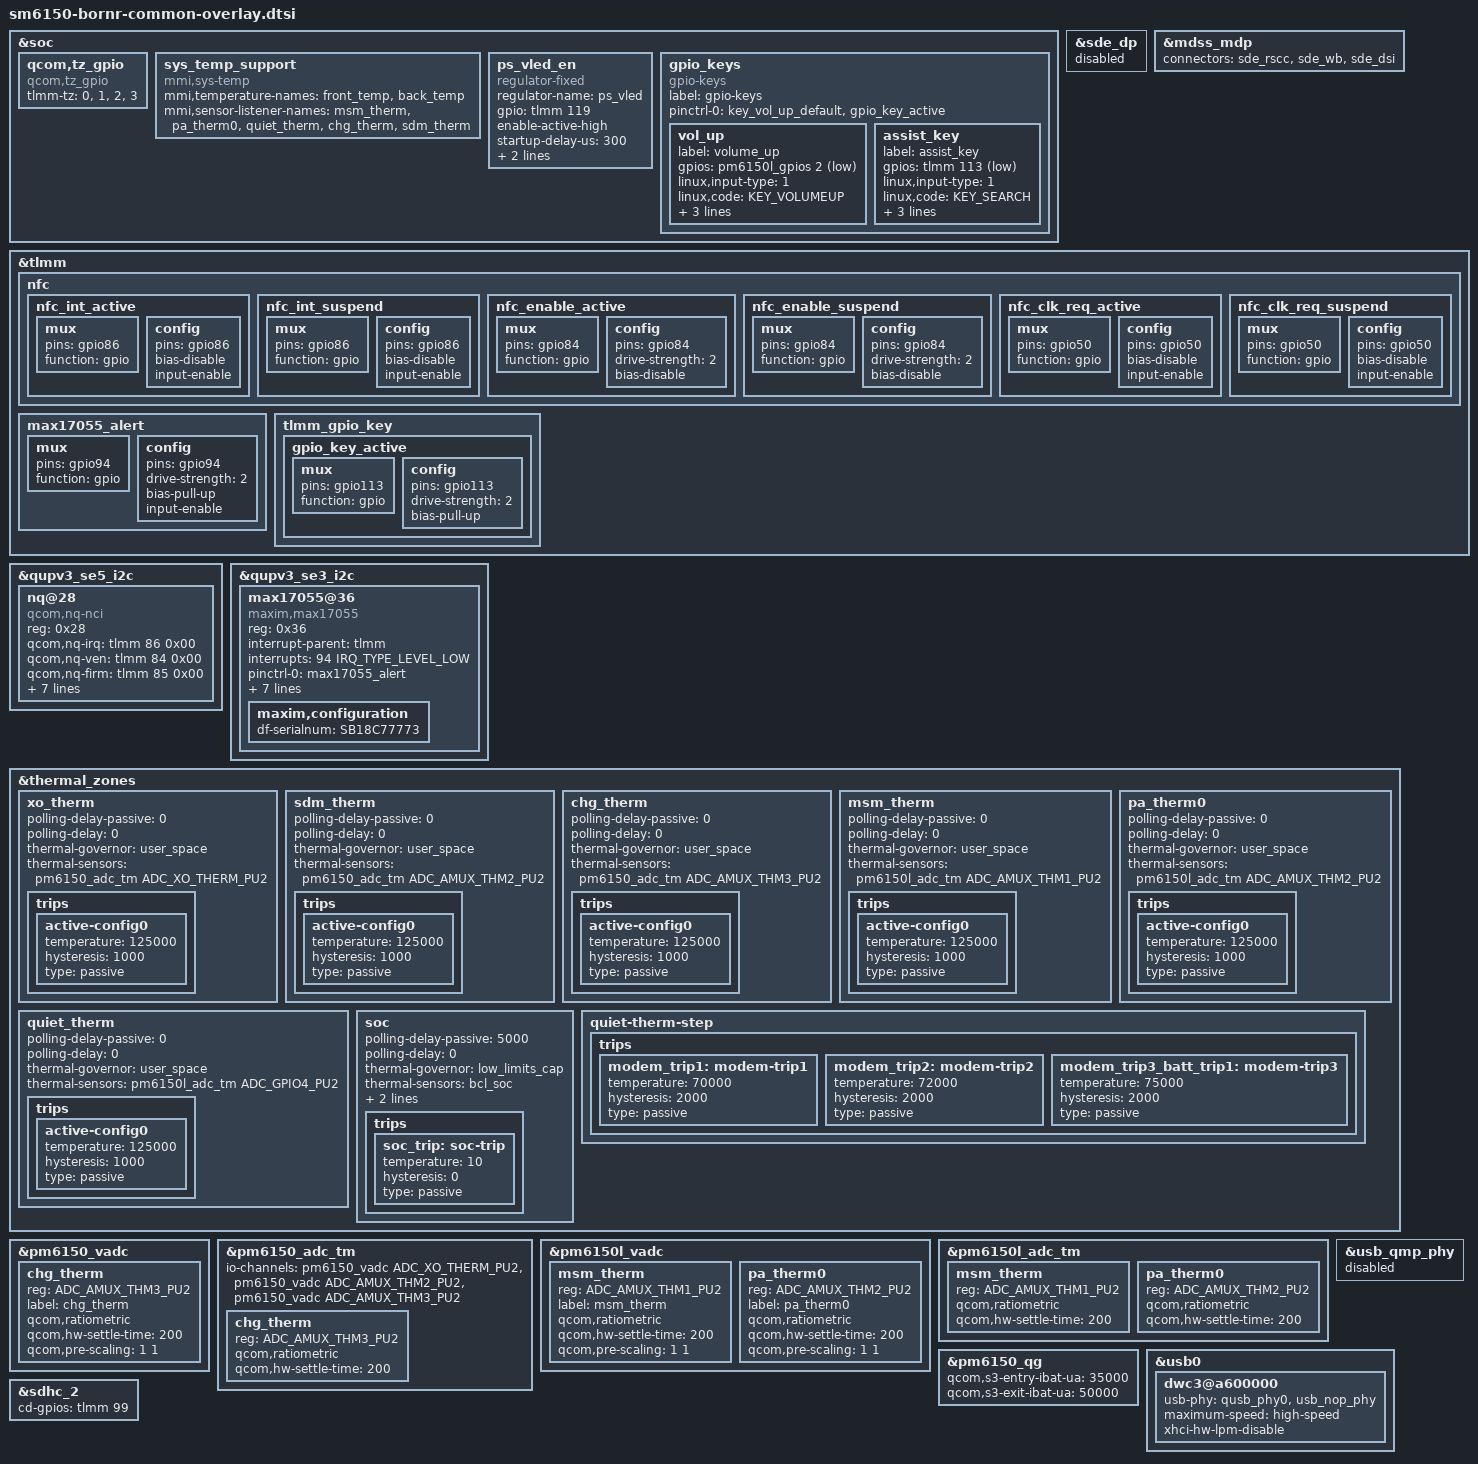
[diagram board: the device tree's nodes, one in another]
/* Copyright (c) 2020, The Linux Foundation. All rights reserved.
 *
 * This program is free software; you can redistribute it and/or modify
 * it under the terms of the GNU General Public License version 2 and
 * only version 2 as published by the Free Software Foundation.
 *
 * This program is distributed in the hope that it will be useful,
 * but WITHOUT ANY WARRANTY; without even the implied warranty of
 * MERCHANTABILITY or FITNESS FOR A PARTICULAR PURPOSE.  See the
 * GNU General Public License for more details.
 */

#include "sm6150-moto-common-overlay.dtsi"
#include "sm6150-camera-sensor-mot-bornr-overlay.dtsi"
#include "bornr-panel.dtsi"
#include "bornr-touchscreen.dtsi"
#include "sm6150-bornr-charger-overlay.dtsi"
#include "sm6150-bornr-sensor-overlay.dtsi"
#include "sm6150-bornr-fps-overlay.dtsi"
#include "sm6150-audio-overlay.dtsi"
#include "sm6150-bornr-audio-overlay.dtsi"

#define BORNR_NONCA_RADIO1 1
#define BORNR_NONCA_RADIO2 2

&soc {
	qcom,tz_gpio {
		compatible = "qcom,tz_gpio";
		tlmm-tz = <0>,
			<1>,
			<2>,
			<3>;
	};

	sys_temp_support {
		compatible = "mmi,sys-temp";
		mmi,temperature-names = "front_temp",
			"back_temp";
		mmi,sensor-listener-names = "msm_therm",
			"pa_therm0", "quiet_therm",
			"chg_therm", "sdm_therm";
		status = "ok";
	};

};

&sde_dp {
	status = "disabled";
};

&mdss_mdp {
       connectors = <&sde_rscc &sde_wb &sde_dsi>;
};

&tlmm{
	nfc {
		nfc_int_active: nfc_int_active {
			/* active state */
			mux {
				/* GPIO86 NFC Read Interrupt */
				pins = "gpio86";
				function = "gpio";
			};

			config {
				pins = "gpio86";
				bias-disable;
				input-enable;
			};
		};

		nfc_int_suspend: nfc_int_suspend {
			/* sleep state */
			mux {
				/* GPIO 86 NFC Read Interrupt */
				pins = "gpio86";
				function = "gpio";
			};

			config {
				pins = "gpio86";
				bias-disable;
				input-enable;
			};
		};

		nfc_enable_active: nfc_enable_active {
			/* active state */
			mux {
				/* 84: NFC ENABLE */
				pins = "gpio84";
				function = "gpio";
			};

			config {
				pins = "gpio84";
				drive-strength = <2>; /* 2 MA */
				bias-disable;
			};
		};

		nfc_enable_suspend: nfc_enable_suspend {
			/* sleep state */
			mux {
				/* 84: NFC ENABLE */
				pins = "gpio84";
				function = "gpio";
			};

			config {
				pins = "gpio84";
				drive-strength = <2>; /* 2 MA */
				bias-disable;
			};
		};

		nfc_clk_req_active: nfc_clk_req_active {
			/* active state */
			mux {
				/* 50: NFC CLOCK REQUEST */
				pins = "gpio50";
				function = "gpio";
			};

			config {
				pins = "gpio50";
				bias-disable;
				input-enable;
			};
		};

		nfc_clk_req_suspend: nfc_clk_req_suspend {
			/* sleep state */
			mux {
				/* 50: NFC CLOCK REQUEST */
				pins = "gpio50";
				function = "gpio";
			};

			config {
				pins = "gpio50";
				bias-disable;
				input-enable;
			};
		};
	};

	max17055_alert: max17055_alert {
		mux {
			pins = "gpio94";
			function = "gpio";
		};

		config {
			pins = "gpio94";
			drive-strength = <2>; /* 2 MA */
			bias-pull-up;
			input-enable;
		};
	};

       /* Pinctrl setting for assist key */
	tlmm_gpio_key {
		gpio_key_active: gpio_key_active {
			mux {
				pins = "gpio113";
				function = "gpio";
			};

			config {
				pins = "gpio113";
				drive-strength = <2>;
				bias-pull-up;
			};
		};
	};
};

&soc {
	ps_vled_en: ps_vled_en {
		compatible = "regulator-fixed";
		regulator-name = "ps_vled";
		gpio = <&tlmm 119 0>;
		enable-active-high;
		startup-delay-us = <300>;
		regulator-boot-on;
		regulator-always-on;
	};

	gpio_keys {
		compatible = "gpio-keys";
		label = "gpio-keys";

		pinctrl-names = "default";
		pinctrl-0 = <&key_vol_up_default &gpio_key_active>;

		vol_up {
			label = "volume_up";
			gpios = <&pm6150l_gpios 2 GPIO_ACTIVE_LOW>;
			linux,input-type = <1>;
			linux,code = <KEY_VOLUMEUP>;
			linux,can-disable;
			debounce-interval = <15>;
			gpio-key,wakeup;
		};

		assist_key{
			label = "assist_key";
			gpios = <&tlmm 113 GPIO_ACTIVE_LOW>;
			linux,input-type = <1>;
			linux,code = <KEY_SEARCH>;
			debounce-interval = <15>;
			linux,can-disable;
			gpio-key,wakeup;
		};
	};
};

&qupv3_se5_i2c {
	status = "ok";
	nq@28 {
		compatible = "qcom,nq-nci";
		status = "ok";
		reg = <0x28>;
		qcom,nq-irq = <&tlmm 86 0x00>;
		qcom,nq-ven = <&tlmm 84 0x00>;
		qcom,nq-firm = <&tlmm 85 0x00>;
		qcom,nq-clkreq = <&tlmm 50 0x00>;
		interrupt-parent = <&tlmm>;
		interrupts = <86 0>;
		interrupt-names = "nfc_irq";
		pinctrl-names = "default", "suspend";
		pinctrl-0 = <&nfc_int_active &nfc_enable_active
				&nfc_clk_req_active>;
		pinctrl-1 = <&nfc_int_suspend &nfc_enable_suspend
				&nfc_clk_req_suspend>;
	};
};

&qupv3_se3_i2c {
	max17055@36 {
            status = "okay";
            compatible = "maxim,max17055";
            reg = <0x36>;

            interrupt-parent = <&tlmm>;
            interrupts = <94 IRQ_TYPE_LEVEL_LOW>;
            pinctrl-names = "default";
            pinctrl-0 = <&max17055_alert>;

            maxim,rsns-microohm = <2000>;      /*Current sense resistance in micro Ohm*/
            maxim,config-type = <3>;            /*EZ:1 SHORT: 2 FULL: 3*/
            maxim,cold-temp = <(-200)>;         /*Temp is scaled by 10 to reserve more precise*/
            maxim,over-heat-temp = <600>;      /*Temp is scaled by 10 to reserve more precise*/
            maxim,dead-volt = <2800>;           /*Dead voltage in millivolts*/
            maxim,over-volt = <4500>;           /*Over voltage in millivolts*/
            maxim,enable-por-init;              /*Comment out this line to ignore the configuration data*/
            maxim,configuration {
		df-serialnum    = "SB18C77773";
		/include/ "batterydata-lk50-atl-maxim.dtsi"
	   };
        };
};

&thermal_zones {
	xo_therm {
		polling-delay-passive = <0>;
		polling-delay = <0>;
		thermal-governor = "user_space";
		thermal-sensors = <&pm6150_adc_tm ADC_XO_THERM_PU2>;
		trips {
			active-config0 {
				temperature = <125000>;
				hysteresis = <1000>;
				type = "passive";
			};
		};
	};

	sdm_therm {
		polling-delay-passive = <0>;
		polling-delay = <0>;
		thermal-governor = "user_space";
		thermal-sensors = <&pm6150_adc_tm ADC_AMUX_THM2_PU2>;
		trips {
			active-config0 {
				temperature = <125000>;
				hysteresis = <1000>;
				type = "passive";
			};
		};
	};

	chg_therm {
		polling-delay-passive = <0>;
		polling-delay = <0>;
		thermal-governor = "user_space";
		thermal-sensors = <&pm6150_adc_tm ADC_AMUX_THM3_PU2>;
		trips {
			active-config0 {
				temperature = <125000>;
				hysteresis = <1000>;
				type = "passive";
			};
		};
	};

	msm_therm {
		polling-delay-passive = <0>;
		polling-delay = <0>;
		thermal-governor = "user_space";
		thermal-sensors = <&pm6150l_adc_tm ADC_AMUX_THM1_PU2>;
		trips {
			active-config0 {
				temperature = <125000>;
				hysteresis = <1000>;
				type = "passive";
			};
		};
	};

	pa_therm0 {
		polling-delay-passive = <0>;
		polling-delay = <0>;
		thermal-governor = "user_space";
		thermal-sensors = <&pm6150l_adc_tm ADC_AMUX_THM2_PU2>;
		trips {
			active-config0 {
				temperature = <125000>;
				hysteresis = <1000>;
				type = "passive";
			};
		};
	};

	quiet_therm {
		polling-delay-passive = <0>;
		polling-delay = <0>;
		thermal-governor = "user_space";
		thermal-sensors = <&pm6150l_adc_tm ADC_GPIO4_PU2>;
		trips {
			active-config0 {
				temperature = <125000>;
				hysteresis = <1000>;
				type = "passive";
			};
		};
	};

	soc {
		polling-delay-passive = <5000>;
		polling-delay = <0>;
		thermal-governor = "low_limits_cap";
		thermal-sensors = <&bcl_soc>;
		wake-capable-sensor;
		tracks-low;

		trips {
			soc_trip:soc-trip {
				temperature = <10>;
				hysteresis = <0>;
				type = "passive";
			};
		};
	};

	quiet-therm-step {
		trips {
			modem_trip1: modem-trip1 {
				temperature = <70000>;
				hysteresis = <2000>;
				type = "passive";
			};
			modem_trip2: modem-trip2 {
				temperature = <72000>;
				hysteresis = <2000>;
				type = "passive";
			};
			modem_trip3_batt_trip1: modem-trip3 {
				temperature = <75000>;
				hysteresis = <2000>;
				type = "passive";
			};
		};
	};
};

&pm6150_vadc {
	chg_therm {
		reg = <ADC_AMUX_THM3_PU2>;
		label = "chg_therm";
		qcom,ratiometric;
		qcom,hw-settle-time = <200>;
		qcom,pre-scaling = <1 1>;
	};
};

&pm6150_adc_tm {
	io-channels = <&pm6150_vadc ADC_XO_THERM_PU2>,
			<&pm6150_vadc ADC_AMUX_THM2_PU2>,
			<&pm6150_vadc ADC_AMUX_THM3_PU2>;

	/* Channel nodes */
	chg_therm {
		reg = <ADC_AMUX_THM3_PU2>;
		qcom,ratiometric;
		qcom,hw-settle-time = <200>;
	};
};

&pm6150l_vadc {
	msm_therm {
		reg = <ADC_AMUX_THM1_PU2>;
		label = "msm_therm";
		qcom,ratiometric;
		qcom,hw-settle-time = <200>;
		qcom,pre-scaling = <1 1>;
	};

	pa_therm0 {
		reg = <ADC_AMUX_THM2_PU2>;
		label = "pa_therm0";
		qcom,ratiometric;
		qcom,hw-settle-time = <200>;
		qcom,pre-scaling = <1 1>;
	};
};

&pm6150l_adc_tm {
	/* Channel nodes */
	msm_therm {
		reg = <ADC_AMUX_THM1_PU2>;
		qcom,ratiometric;
		qcom,hw-settle-time = <200>;
	};

	pa_therm0 {
		reg = <ADC_AMUX_THM2_PU2>;
		qcom,ratiometric;
		qcom,hw-settle-time = <200>;
	};
};

&pm6150_qg {
	qcom,s3-entry-ibat-ua = <35000>;
	qcom,s3-exit-ibat-ua = <50000>;
};

&usb_qmp_phy {
	status = "disabled";
};

&usb0 {
	dwc3@a600000 {
		usb-phy = <&qusb_phy0>, <&usb_nop_phy>;
		maximum-speed = "high-speed";
		xhci-hw-lpm-disable;
	};
};
&sdhc_2 {
	cd-gpios = <&tlmm 99 0>;
};
